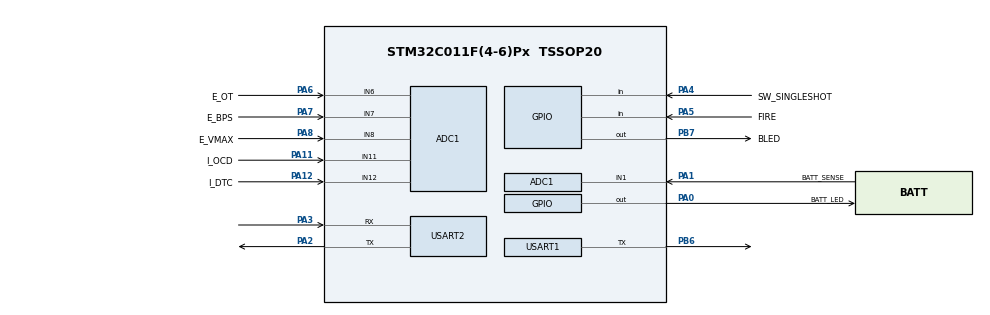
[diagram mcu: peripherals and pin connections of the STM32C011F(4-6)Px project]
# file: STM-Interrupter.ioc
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ADC1.Channel-0\#ChannelRegularConversion=ADC_CHANNEL_1
ADC1.Channel-1\#ChannelRegularConversion=ADC_CHANNEL_6
ADC1.Channel-2\#ChannelRegularConversion=ADC_CHANNEL_7
ADC1.Channel-3\#ChannelRegularConversion=ADC_CHANNEL_8
ADC1.Channel-4\#ChannelRegularConversion=ADC_CHANNEL_11
ADC1.Channel-5\#ChannelRegularConversion=ADC_CHANNEL_12
ADC1.Channel-6\#ChannelRegularConversion=ADC_CHANNEL_TEMPSENSOR
ADC1.Channel-7\#ChannelRegularConversion=ADC_CHANNEL_VREFINT
ADC1.ContinuousConvMode=ENABLE
ADC1.DMAContinuousRequests=ENABLE
ADC1.EOCSelection=ADC_EOC_SEQ_CONV
ADC1.NbrOfConversion=8
ADC1.NbrOfConversionFlag=1
ADC1.OversamplingMode=ENABLE
ADC1.Rank-0\#ChannelRegularConversion=1
ADC1.Rank-1\#ChannelRegularConversion=2
ADC1.Rank-2\#ChannelRegularConversion=3
ADC1.Rank-3\#ChannelRegularConversion=4
ADC1.Rank-4\#ChannelRegularConversion=5
ADC1.Rank-5\#ChannelRegularConversion=6
ADC1.Rank-6\#ChannelRegularConversion=7
ADC1.Rank-7\#ChannelRegularConversion=8
ADC1.Ratio=ADC_OVERSAMPLING_RATIO_64
ADC1.RightBitShift=ADC_RIGHTBITSHIFT_6
ADC1.SamplingTime-0\#ChannelRegularConversion=ADC_SAMPLINGTIME_COMMON_1
ADC1.SamplingTime-1\#ChannelRegularConversion=ADC_SAMPLINGTIME_COMMON_1
ADC1.SamplingTime-2\#ChannelRegularConversion=ADC_SAMPLINGTIME_COMMON_1
ADC1.SamplingTime-3\#ChannelRegularConversion=ADC_SAMPLINGTIME_COMMON_1
ADC1.SamplingTime-4\#ChannelRegularConversion=ADC_SAMPLINGTIME_COMMON_1
ADC1.SamplingTime-5\#ChannelRegularConversion=ADC_SAMPLINGTIME_COMMON_1
ADC1.SamplingTime-6\#ChannelRegularConversion=ADC_SAMPLINGTIME_COMMON_1
ADC1.SamplingTime-7\#ChannelRegularConversion=ADC_SAMPLINGTIME_COMMON_1
ADC1.SamplingTimeCommon1=ADC_SAMPLETIME_160CYCLES_5
ADC1.SamplingTimeCommon2=ADC_SAMPLETIME_160CYCLES_5
ADC1.SelectedChannel=ADC_CHANNEL_1|ADC_CHANNEL_6|ADC_CHANNEL_7|ADC_CHANNEL_TEMPSENSOR|ADC_CHANNEL_VREFINT|ADC_CHANNEL_8|ADC_CHANNEL_11|ADC_CHANNEL_12
ADC1.Sequencer=FULLY_CONFIGURABLE
ADC1.TriggeredMode=ADC_TRIGGEREDMODE_SINGLE_TRIGGER
ADC1.master=1
Dma.ADC1.0.Direction=DMA_PERIPH_TO_MEMORY
Dma.ADC1.0.EventEnable=DISABLE
Dma.ADC1.0.Instance=DMA1_Channel1
Dma.ADC1.0.MemDataAlignment=DMA_MDATAALIGN_HALFWORD
Dma.ADC1.0.MemInc=DMA_MINC_ENABLE
Dma.ADC1.0.Mode=DMA_CIRCULAR
Dma.ADC1.0.PeriphDataAlignment=DMA_PDATAALIGN_HALFWORD
Dma.ADC1.0.PeriphInc=DMA_PINC_DISABLE
Dma.ADC1.0.Polarity=HAL_DMAMUX_REQ_GEN_RISING
Dma.ADC1.0.Priority=DMA_PRIORITY_LOW
Dma.ADC1.0.RequestNumber=1
Dma.ADC1.0.SignalID=NONE
Dma.ADC1.0.SyncEnable=DISABLE
Dma.ADC1.0.SyncPolarity=HAL_DMAMUX_SYNC_NO_EVENT
Dma.ADC1.0.SyncRequestNumber=1
Dma.ADC1.0.SyncSignalID=NONE
Dma.Request0=ADC1
Mcu.Family=STM32C0
Mcu.Name=STM32C011F(4-6)Px
Mcu.Package=TSSOP20
NVIC.DMA1_Channel1_IRQn=true\:0\:0\:false\:false\:true\:false\:true\:true
NVIC.TIM16_IRQn=true\:0\:0\:false\:false\:true\:true\:true\:true
NVIC.TIM17_IRQn=true\:0\:0\:false\:false\:true\:true\:true\:true
NVIC.USART2_IRQn=true\:0\:0\:false\:false\:true\:true\:true\:true
PA0.GPIO_Label=BATT_LED
PA0.Signal=GPIO_Output
PA1.GPIO_Label=BATT_SENSE
PA1.Mode=IN1
PA1.Signal=ADC1_IN1
PA11\ [PA9].GPIO_Label=I_OCD
PA11\ [PA9].Mode=IN11
PA11\ [PA9].Signal=ADC1_IN11
PA12\ [PA10].GPIO_Label=I_DTC
PA12\ [PA10].Mode=IN12
PA12\ [PA10].Signal=ADC1_IN12
PA13.Mode=Serial_Wire
PA13.Signal=DEBUG_SWDIO
PA14-BOOT0.Mode=Serial_Wire
PA14-BOOT0.Signal=DEBUG_SWCLK
PA2.Mode=Asynchronous
PA2.Signal=USART2_TX
PA3.Mode=Asynchronous
PA3.Signal=USART2_RX
PA4.GPIO_Label=SW_SINGLESHOT
PA4.Signal=GPIO_Input
PA5.GPIO_Label=FIRE
PA5.Signal=GPIO_Input
PA6.GPIO_Label=E_OT
PA6.Mode=IN6
PA6.Signal=ADC1_IN6
PA7.GPIO_Label=E_BPS
PA7.Mode=IN7
PA7.Signal=ADC1_IN7
PA8.GPIO_Label=E_VMAX
PA8.Mode=IN8
PA8.Signal=ADC1_IN8
PB6.Mode=Half_duplex(single_wire_mode)
PB6.Signal=USART1_TX
PB7.GPIO_Label=BLED
PB7.Signal=GPIO_Output
PC14-OSCX_IN\ (PC14).Mode=HSE-External-Oscillator-REMAPPED
PC14-OSCX_IN\ (PC14).Signal=RCC_OSCX_IN
PC15-OSCX_OUT\ (PC15).Mode=HSE-External-Oscillator-REMAPPED
PC15-OSCX_OUT\ (PC15).Signal=RCC_OSCX_OUT
ProjectManager.HeapSize=0x200
ProjectManager.StackSize=0x400
ProjectManager.TargetToolchain=STM32CubeIDE
RCC.ADCFreq_Value=24000000
RCC.AHBFreq_Value=24000000
RCC.CortexFreq_Value=24000000
RCC.EXTERNAL_CLOCK_VALUE=12288000
RCC.HCLKFreq_Value=24000000
RCC.HSE_VALUE=24000000
RCC.HSI_VALUE=48000000
RCC.LSE_VALUE=32768
RCC.SYSCLKFreq_VALUE=24000000
RCC.SYSCLKSource=RCC_SYSCLKSOURCE_HSE
TIM16.Prescaler=65535
TIM17.Period=10000
TIM17.Prescaler=23
TIM3.Period=10000
TIM3.Prescaler=23
USART1.Mode=MODE_TX
USART1.RxPinLevelInvertParam=ADVFEATURE_RXINV_ENABLE
USART1.TxPinLevelInvertParam=ADVFEATURE_TXINV_ENABLE
USART1.VirtualMode-Half_duplex(single_wire_mode)=VM_ASYNC
USART2.VirtualMode-Asynchronous=VM_ASYNC
VP_ADC1_TempSens_Input.Mode=IN-TempSens
VP_ADC1_Vref_Input.Mode=IN-Vrefint
VP_TIM16_VS_ClockSourceINT.Mode=Enable_Timer
VP_TIM17_VS_ClockSourceINT.Mode=Enable_Timer
VP_TIM3_VS_OPM.Mode=OPM_bit
board=custom

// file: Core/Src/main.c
/* USER CODE BEGIN Header */
/**
  ******************************************************************************
  * @file           : main.c
  * @brief          : Main program body
  ******************************************************************************
  * @attention
  *
  * Copyright (c) 2025 STMicroelectronics.
  * All rights reserved.
  *
  * This software is licensed under terms that can be found in the LICENSE file
  * in the root directory of this software component.
  * If no LICENSE file comes with this software, it is provided AS-IS.
  *
  ******************************************************************************
  */
/* USER CODE END Header */
#include "main.h"

ADC_HandleTypeDef hadc1;
DMA_HandleTypeDef hdma_adc1;

TIM_HandleTypeDef htim3;
TIM_HandleTypeDef htim16;
TIM_HandleTypeDef htim17;

UART_HandleTypeDef huart1;
UART_HandleTypeDef huart2;

void SystemClock_Config(void);
static void MX_GPIO_Init(void);
static void MX_DMA_Init(void);
static void MX_ADC1_Init(void);
static void MX_USART1_UART_Init(void);
static void MX_USART2_UART_Init(void);
static void MX_TIM17_Init(void);
static void MX_TIM16_Init(void);
static void MX_TIM3_Init(void);

int main(void)
{

  /* MCU Configuration--------------------------------------------------------*/

  /* Reset of all peripherals, Initializes the Flash interface and the Systick. */
  HAL_Init();

  /* Configure the system clock */
  SystemClock_Config();

  /* Initialize all configured peripherals */
  MX_GPIO_Init();
  MX_DMA_Init();
  MX_ADC1_Init();
  MX_USART1_UART_Init();
  MX_USART2_UART_Init();
  MX_TIM17_Init();
  MX_TIM16_Init();
  MX_TIM3_Init();
  /* USER CODE BEGIN 2 */
  IntInit();
  /* USER CODE END 2 */

  /* Infinite loop */
  while (1)
  {

  }
}

void SystemClock_Config(void)
{
  RCC_OscInitTypeDef RCC_OscInitStruct = {0};
  RCC_ClkInitTypeDef RCC_ClkInitStruct = {0};

  /** Initializes the RCC Oscillators according to the specified parameters
  * in the RCC_OscInitTypeDef structure.
  */
  RCC_OscInitStruct.OscillatorType = RCC_OSCILLATORTYPE_HSE;
  RCC_OscInitStruct.HSEState = RCC_HSE_ON;
  if (HAL_RCC_OscConfig(&RCC_OscInitStruct) != HAL_OK)
  {
    Error_Handler();
  }

  /** Initializes the CPU, AHB and APB buses clocks
  */
  RCC_ClkInitStruct.ClockType = RCC_CLOCKTYPE_HCLK|RCC_CLOCKTYPE_SYSCLK
                              |RCC_CLOCKTYPE_PCLK1;
  RCC_ClkInitStruct.SYSCLKSource = RCC_SYSCLKSOURCE_HSE;
  RCC_ClkInitStruct.SYSCLKDivider = RCC_SYSCLK_DIV1;
  RCC_ClkInitStruct.AHBCLKDivider = RCC_HCLK_DIV1;
  RCC_ClkInitStruct.APB1CLKDivider = RCC_APB1_DIV1;

  if (HAL_RCC_ClockConfig(&RCC_ClkInitStruct, FLASH_LATENCY_0) != HAL_OK)
  {
    Error_Handler();
  }
}

static void MX_ADC1_Init(void)
{

  ADC_ChannelConfTypeDef sConfig = {0};

  /** Configure the global features of the ADC (Clock, Resolution, Data Alignment and number of conversion)
  */
  hadc1.Instance = ADC1;
  hadc1.Init.ClockPrescaler = ADC_CLOCK_SYNC_PCLK_DIV1;
  hadc1.Init.Resolution = ADC_RESOLUTION_12B;
  hadc1.Init.DataAlign = ADC_DATAALIGN_RIGHT;
  hadc1.Init.ScanConvMode = ADC_SCAN_ENABLE;
  hadc1.Init.EOCSelection = ADC_EOC_SEQ_CONV;
  hadc1.Init.LowPowerAutoWait = DISABLE;
  hadc1.Init.LowPowerAutoPowerOff = DISABLE;
  hadc1.Init.ContinuousConvMode = ENABLE;
  hadc1.Init.NbrOfConversion = 8;
  hadc1.Init.ExternalTrigConv = ADC_SOFTWARE_START;
  hadc1.Init.ExternalTrigConvEdge = ADC_EXTERNALTRIGCONVEDGE_NONE;
  hadc1.Init.DMAContinuousRequests = ENABLE;
  hadc1.Init.Overrun = ADC_OVR_DATA_PRESERVED;
  hadc1.Init.SamplingTimeCommon1 = ADC_SAMPLETIME_160CYCLES_5;
  hadc1.Init.SamplingTimeCommon2 = ADC_SAMPLETIME_160CYCLES_5;
  hadc1.Init.OversamplingMode = ENABLE;
  hadc1.Init.Oversampling.Ratio = ADC_OVERSAMPLING_RATIO_64;
  hadc1.Init.Oversampling.RightBitShift = ADC_RIGHTBITSHIFT_6;
  hadc1.Init.Oversampling.TriggeredMode = ADC_TRIGGEREDMODE_SINGLE_TRIGGER;
  hadc1.Init.TriggerFrequencyMode = ADC_TRIGGER_FREQ_HIGH;
  if (HAL_ADC_Init(&hadc1) != HAL_OK)
  {
    Error_Handler();
  }

  /** Configure Regular Channel
  */
  sConfig.Channel = ADC_CHANNEL_1;
  sConfig.Rank = ADC_REGULAR_RANK_1;
  sConfig.SamplingTime = ADC_SAMPLINGTIME_COMMON_1;
  if (HAL_ADC_ConfigChannel(&hadc1, &sConfig) != HAL_OK)
  {
    Error_Handler();
  }

  /** Configure Regular Channel
  */
  sConfig.Channel = ADC_CHANNEL_6;
  sConfig.Rank = ADC_REGULAR_RANK_2;
  if (HAL_ADC_ConfigChannel(&hadc1, &sConfig) != HAL_OK)
  {
    Error_Handler();
  }

  /** Configure Regular Channel
  */
  sConfig.Channel = ADC_CHANNEL_7;
  sConfig.Rank = ADC_REGULAR_RANK_3;
  if (HAL_ADC_ConfigChannel(&hadc1, &sConfig) != HAL_OK)
  {
    Error_Handler();
  }

  /** Configure Regular Channel
  */
  sConfig.Channel = ADC_CHANNEL_8;
  sConfig.Rank = ADC_REGULAR_RANK_4;
  if (HAL_ADC_ConfigChannel(&hadc1, &sConfig) != HAL_OK)
  {
    Error_Handler();
  }

  /** Configure Regular Channel
  */
  sConfig.Channel = ADC_CHANNEL_11;
  sConfig.Rank = ADC_REGULAR_RANK_5;
  if (HAL_ADC_ConfigChannel(&hadc1, &sConfig) != HAL_OK)
  {
    Error_Handler();
  }

  /** Configure Regular Channel
  */
  sConfig.Channel = ADC_CHANNEL_12;
  sConfig.Rank = ADC_REGULAR_RANK_6;
  if (HAL_ADC_ConfigChannel(&hadc1, &sConfig) != HAL_OK)
  {
    Error_Handler();
  }

  /** Configure Regular Channel
  */
  sConfig.Channel = ADC_CHANNEL_TEMPSENSOR;
  sConfig.Rank = ADC_REGULAR_RANK_7;
  if (HAL_ADC_ConfigChannel(&hadc1, &sConfig) != HAL_OK)
  {
    Error_Handler();
  }

  /** Configure Regular Channel
  */
  sConfig.Channel = ADC_CHANNEL_VREFINT;
  sConfig.Rank = ADC_REGULAR_RANK_8;
  if (HAL_ADC_ConfigChannel(&hadc1, &sConfig) != HAL_OK)
  {
    Error_Handler();
  }

}

static void MX_TIM3_Init(void)
{

  TIM_MasterConfigTypeDef sMasterConfig = {0};

  htim3.Instance = TIM3;
  htim3.Init.Prescaler = 23;
  htim3.Init.CounterMode = TIM_COUNTERMODE_UP;
  htim3.Init.Period = 10000;
  htim3.Init.ClockDivision = TIM_CLOCKDIVISION_DIV1;
  htim3.Init.AutoReloadPreload = TIM_AUTORELOAD_PRELOAD_DISABLE;
  if (HAL_TIM_OnePulse_Init(&htim3, TIM_OPMODE_SINGLE) != HAL_OK)
  {
    Error_Handler();
  }
  sMasterConfig.MasterOutputTrigger = TIM_TRGO_RESET;
  sMasterConfig.MasterSlaveMode = TIM_MASTERSLAVEMODE_DISABLE;
  if (HAL_TIMEx_MasterConfigSynchronization(&htim3, &sMasterConfig) != HAL_OK)
  {
    Error_Handler();
  }

}

static void MX_TIM16_Init(void)
{

  htim16.Instance = TIM16;
  htim16.Init.Prescaler = 65535;
  htim16.Init.CounterMode = TIM_COUNTERMODE_UP;
  htim16.Init.Period = 65535;
  htim16.Init.ClockDivision = TIM_CLOCKDIVISION_DIV1;
  htim16.Init.RepetitionCounter = 0;
  htim16.Init.AutoReloadPreload = TIM_AUTORELOAD_PRELOAD_DISABLE;
  if (HAL_TIM_Base_Init(&htim16) != HAL_OK)
  {
    Error_Handler();
  }

}

static void MX_TIM17_Init(void)
{

  htim17.Instance = TIM17;
  htim17.Init.Prescaler = 23;
  htim17.Init.CounterMode = TIM_COUNTERMODE_UP;
  htim17.Init.Period = 10000;
  htim17.Init.ClockDivision = TIM_CLOCKDIVISION_DIV1;
  htim17.Init.RepetitionCounter = 0;
  htim17.Init.AutoReloadPreload = TIM_AUTORELOAD_PRELOAD_DISABLE;
  if (HAL_TIM_Base_Init(&htim17) != HAL_OK)
  {
    Error_Handler();
  }

}

static void MX_USART1_UART_Init(void)
{

  huart1.Instance = USART1;
  huart1.Init.BaudRate = 115200;
  huart1.Init.WordLength = UART_WORDLENGTH_8B;
  huart1.Init.StopBits = UART_STOPBITS_1;
  huart1.Init.Parity = UART_PARITY_NONE;
  huart1.Init.Mode = UART_MODE_TX;
  huart1.Init.HwFlowCtl = UART_HWCONTROL_NONE;
  huart1.Init.OverSampling = UART_OVERSAMPLING_16;
  huart1.Init.OneBitSampling = UART_ONE_BIT_SAMPLE_DISABLE;
  huart1.Init.ClockPrescaler = UART_PRESCALER_DIV1;
  huart1.AdvancedInit.AdvFeatureInit = UART_ADVFEATURE_TXINVERT_INIT|UART_ADVFEATURE_RXINVERT_INIT;
  huart1.AdvancedInit.TxPinLevelInvert = UART_ADVFEATURE_TXINV_ENABLE;
  huart1.AdvancedInit.RxPinLevelInvert = UART_ADVFEATURE_RXINV_ENABLE;
  if (HAL_HalfDuplex_Init(&huart1) != HAL_OK)
  {
    Error_Handler();
  }
  if (HAL_UARTEx_SetTxFifoThreshold(&huart1, UART_TXFIFO_THRESHOLD_1_8) != HAL_OK)
  {
    Error_Handler();
  }
  if (HAL_UARTEx_SetRxFifoThreshold(&huart1, UART_RXFIFO_THRESHOLD_1_8) != HAL_OK)
  {
    Error_Handler();
  }
  if (HAL_UARTEx_DisableFifoMode(&huart1) != HAL_OK)
  {
    Error_Handler();
  }

}

static void MX_USART2_UART_Init(void)
{

  huart2.Instance = USART2;
  huart2.Init.BaudRate = 115200;
  huart2.Init.WordLength = UART_WORDLENGTH_8B;
  huart2.Init.StopBits = UART_STOPBITS_1;
  huart2.Init.Parity = UART_PARITY_NONE;
  huart2.Init.Mode = UART_MODE_TX_RX;
  huart2.Init.HwFlowCtl = UART_HWCONTROL_NONE;
  huart2.Init.OverSampling = UART_OVERSAMPLING_16;
  huart2.Init.OneBitSampling = UART_ONE_BIT_SAMPLE_DISABLE;
  huart2.Init.ClockPrescaler = UART_PRESCALER_DIV1;
  huart2.AdvancedInit.AdvFeatureInit = UART_ADVFEATURE_NO_INIT;
  if (HAL_UART_Init(&huart2) != HAL_OK)
  {
    Error_Handler();
  }

}

static void MX_DMA_Init(void)
{

  /* DMA controller clock enable */
  __HAL_RCC_DMA1_CLK_ENABLE();

  /* DMA interrupt init */
  /* DMA1_Channel1_IRQn interrupt configuration */
  HAL_NVIC_SetPriority(DMA1_Channel1_IRQn, 0, 0);
  HAL_NVIC_EnableIRQ(DMA1_Channel1_IRQn);

}

static void MX_GPIO_Init(void)
{
  GPIO_InitTypeDef GPIO_InitStruct = {0};

  /* GPIO Ports Clock Enable */
  __HAL_RCC_GPIOB_CLK_ENABLE();
  __HAL_RCC_GPIOC_CLK_ENABLE();
  __HAL_RCC_GPIOA_CLK_ENABLE();

  /*Configure GPIO pin Output Level */
  HAL_GPIO_WritePin(BLED_GPIO_Port, BLED_Pin, GPIO_PIN_RESET);

  /*Configure GPIO pin Output Level */
  HAL_GPIO_WritePin(BATT_LED_GPIO_Port, BATT_LED_Pin, GPIO_PIN_RESET);

  /*Configure GPIO pin : BLED_Pin */
  GPIO_InitStruct.Pin = BLED_Pin;
  GPIO_InitStruct.Mode = GPIO_MODE_OUTPUT_PP;
  GPIO_InitStruct.Pull = GPIO_NOPULL;
  GPIO_InitStruct.Speed = GPIO_SPEED_FREQ_LOW;
  HAL_GPIO_Init(BLED_GPIO_Port, &GPIO_InitStruct);

  /*Configure GPIO pin : BATT_LED_Pin */
  GPIO_InitStruct.Pin = BATT_LED_Pin;
  GPIO_InitStruct.Mode = GPIO_MODE_OUTPUT_PP;
  GPIO_InitStruct.Pull = GPIO_NOPULL;
  GPIO_InitStruct.Speed = GPIO_SPEED_FREQ_LOW;
  HAL_GPIO_Init(BATT_LED_GPIO_Port, &GPIO_InitStruct);

  /*Configure GPIO pins : SW_SINGLESHOT_Pin FIRE_Pin */
  GPIO_InitStruct.Pin = SW_SINGLESHOT_Pin|FIRE_Pin;
  GPIO_InitStruct.Mode = GPIO_MODE_INPUT;
  GPIO_InitStruct.Pull = GPIO_NOPULL;
  HAL_GPIO_Init(GPIOA, &GPIO_InitStruct);

}

void Error_Handler(void)
{
  __disable_irq();
  while (1)
  {
  }
}
